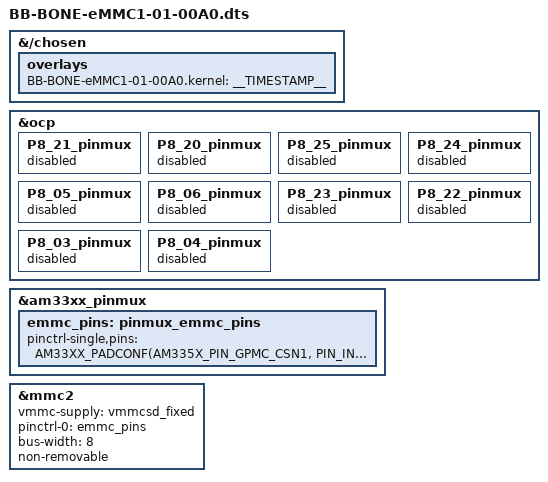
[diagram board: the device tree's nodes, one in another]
// SPDX-License-Identifier: GPL-2.0-only
/*
 * Copyright (C) 2012 Texas Instruments Incorporated - https://www.ti.com/
 */

/dts-v1/;
/plugin/;

#include <dt-bindings/gpio/gpio.h>
#include <dt-bindings/pinctrl/am33xx.h>

/*
 * Helper to show loaded overlays under: /proc/device-tree/chosen/overlays/
 */
&{/chosen} {
	overlays {
		BB-BONE-eMMC1-01-00A0.kernel = __TIMESTAMP__;
	};
};

/*
 * Free up the pins used by the cape from the pinmux helpers.
 */
&ocp {
	P8_21_pinmux { status = "disabled"; };	/* mmc1_clk */
	P8_20_pinmux { status = "disabled"; };	/* mmc1_cmd */
	P8_25_pinmux { status = "disabled"; };	/* mmc1_dat0 */
	P8_24_pinmux { status = "disabled"; };	/* mmc1_dat1 */
	P8_05_pinmux { status = "disabled"; };	/* mmc1_dat2 */
	P8_06_pinmux { status = "disabled"; };	/* mmc1_dat3 */
	P8_23_pinmux { status = "disabled"; };	/* mmc1_dat4 */
	P8_22_pinmux { status = "disabled"; };	/* mmc1_dat5 */
	P8_03_pinmux { status = "disabled"; };	/* mmc1_dat6 */
	P8_04_pinmux { status = "disabled"; };	/* mmc1_dat7 */
};

&am33xx_pinmux {
	emmc_pins: pinmux_emmc_pins {
		pinctrl-single,pins = <
			AM33XX_PADCONF(AM335X_PIN_GPMC_CSN1, PIN_INPUT_PULLUP, MUX_MODE2) /* gpmc_csn1.mmc1_clk */
			AM33XX_PADCONF(AM335X_PIN_GPMC_CSN2, PIN_INPUT_PULLUP, MUX_MODE2) /* gpmc_csn2.mmc1_cmd */
			AM33XX_PADCONF(AM335X_PIN_GPMC_AD0, PIN_INPUT_PULLUP, MUX_MODE1) /* gpmc_ad0.mmc1_dat0 */
			AM33XX_PADCONF(AM335X_PIN_GPMC_AD1, PIN_INPUT_PULLUP, MUX_MODE1) /* gpmc_ad1.mmc1_dat1 */
			AM33XX_PADCONF(AM335X_PIN_GPMC_AD2, PIN_INPUT_PULLUP, MUX_MODE1) /* gpmc_ad2.mmc1_dat2 */
			AM33XX_PADCONF(AM335X_PIN_GPMC_AD3, PIN_INPUT_PULLUP, MUX_MODE1) /* gpmc_ad3.mmc1_dat3 */
			AM33XX_PADCONF(AM335X_PIN_GPMC_AD4, PIN_INPUT_PULLUP, MUX_MODE1) /* gpmc_ad4.mmc1_dat4 */
			AM33XX_PADCONF(AM335X_PIN_GPMC_AD5, PIN_INPUT_PULLUP, MUX_MODE1) /* gpmc_ad5.mmc1_dat5 */
			AM33XX_PADCONF(AM335X_PIN_GPMC_AD6, PIN_INPUT_PULLUP, MUX_MODE1) /* gpmc_ad6.mmc1_dat6 */
			AM33XX_PADCONF(AM335X_PIN_GPMC_AD7, PIN_INPUT_PULLUP, MUX_MODE1) /* gpmc_ad7.mmc1_dat7 */
		>;
	};
};

&mmc2 {
	vmmc-supply = <&vmmcsd_fixed>;
	pinctrl-names = "default";
	pinctrl-0 = <&emmc_pins>;
	bus-width = <8>;
	status = "okay";
	non-removable;
};
